# MKV46F16 register map
Vendor: Freescale Semiconductor, Inc.; Series: Kinetis_V; File version: 1.6
CPU: CM4 r0p1, little endian, no MPU, FPU, VTOR, 4 interrupt priority bits
Registers are 32-bit, read-write, reset 0x0 unless marked. A register's access mark holds for its fields unless they carry their own. Offsets are from the block's base; [hi:lo] are bit positions; {n}, {i} and the like mark numbered series; 'fields as' and 'values as' point back to an identical list.

## XBARA — Crossbar Switch
Base 0x40059000; register names take the prefix XBARA_
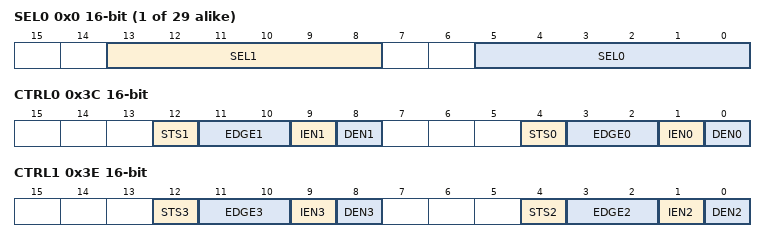
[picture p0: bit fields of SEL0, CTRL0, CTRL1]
{0x0+2i} SEL{i} 16-bit (i=0..28) — Crossbar A Select Register {i}
  [13:8] SEL{2i+1} — Input (XBARA_INn) to be muxed to XBARA_OUT{2i+1} (refer to Functional Description section for input/output assignment)
  [5:0] SEL{2i} — Input (XBARA_INn) to be muxed to XBARA_OUT{2i} (refer to Functional Description section for input/output assignment)
0x3A SEL29 16-bit — Crossbar A Select Register 29
  [5:0] SEL58 — Input (XBARA_INn) to be muxed to XBARA_OUT58 (refer to Functional Description section for input/output assignment)
0x3C CTRL0 16-bit — Crossbar A Control Register 0
  [12] STS1 — Edge detection status for XBAR_OUT1
    0=Active edge not yet detected on XBAR_OUT1; 1=Active edge detected on XBAR_OUT1
  [11:10] EDGE1 — Active edge for edge detection on XBAR_OUT1
    0=STS1 never asserts; 1=STS1 asserts on rising edges of XBAR_OUT1; 2=STS1 asserts on falling edges of XBAR_OUT1; 3=STS1 asserts on rising and falling edges of XBAR_OUT1
  [9] IEN1 — Interrupt Enable for XBAR_OUT1
    0=Interrupt disabled; 1=Interrupt enabled
  [8] DEN1 — DMA Enable for XBAR_OUT1
    0=DMA disabled; 1=DMA enabled
  [4] STS0 — Edge detection status for XBAR_OUT0
    0=Active edge not yet detected on XBAR_OUT0; 1=Active edge detected on XBAR_OUT0
  [3:2] EDGE0 — Active edge for edge detection on XBAR_OUT0
    0=STS0 never asserts; 1=STS0 asserts on rising edges of XBAR_OUT0; 2=STS0 asserts on falling edges of XBAR_OUT0; 3=STS0 asserts on rising and falling edges of XBAR_OUT0
  [1] IEN0 — Interrupt Enable for XBAR_OUT0
    0=Interrupt disabled; 1=Interrupt enabled
  [0] DEN0 — DMA Enable for XBAR_OUT0
    0=DMA disabled; 1=DMA enabled
0x3E CTRL1 16-bit — Crossbar A Control Register 1
  [12] STS3 — Edge detection status for XBAR_OUT3
    0=Active edge not yet detected on XBAR_OUT3; 1=Active edge detected on XBAR_OUT3
  [11:10] EDGE3 — Active edge for edge detection on XBAR_OUT3
    0=STS3 never asserts; 1=STS3 asserts on rising edges of XBAR_OUT3; 2=STS3 asserts on falling edges of XBAR_OUT3; 3=STS3 asserts on rising and falling edges of XBAR_OUT3
  [9] IEN3 — Interrupt Enable for XBAR_OUT3
    0=Interrupt disabled; 1=Interrupt enabled
  [8] DEN3 — DMA Enable for XBAR_OUT3
    0=DMA disabled; 1=DMA enabled
  [4] STS2 — Edge detection status for XBAR_OUT2
    0=Active edge not yet detected on XBAR_OUT2; 1=Active edge detected on XBAR_OUT2
  [3:2] EDGE2 — Active edge for edge detection on XBAR_OUT2
    0=STS2 never asserts; 1=STS2 asserts on rising edges of XBAR_OUT2; 2=STS2 asserts on falling edges of XBAR_OUT2; 3=STS2 asserts on rising and falling edges of XBAR_OUT2
  [1] IEN2 — Interrupt Enable for XBAR_OUT2
    0=Interrupt disabled; 1=Interrupt enabled
  [0] DEN2 — DMA Enable for XBAR_OUT2
    0=DMA disabled; 1=DMA enabled

## XBARB — Crossbar Switch
Base 0x4005A000; register names take the prefix XBARB_
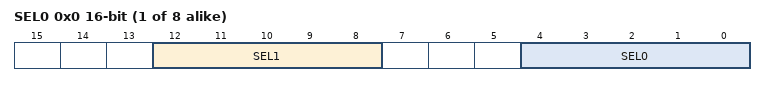
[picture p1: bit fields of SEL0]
{0x0+2i} SEL{i} 16-bit (i=0..7) — Crossbar B Select Register {i}
  [12:8] SEL{2i+1} — Input (XBARB_INn) to be muxed to XBARB_OUT{2i+1} (refer to Functional Description section for input/output assignment)
  [4:0] SEL{2i} — Input (XBARB_INn) to be muxed to XBARB_OUT{2i} (refer to Functional Description section for input/output assignment)

## AOI — AND/OR/INVERT module
Base 0x4005B000; register names take the prefix AOI_
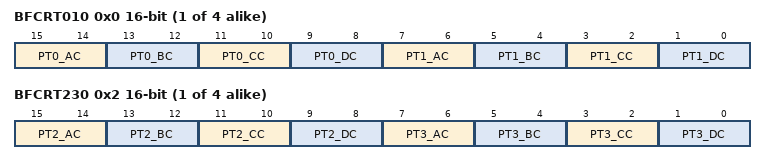
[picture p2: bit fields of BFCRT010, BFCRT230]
{0x0+4i} BFCRT01{i} (i=0..3) 16-bit — Boolean Function Term 0 and 1 Configuration Register for EVENTn
  [15:14] PT0_AC — Product term 0, A input configuration
    0=Force the A input in this product term to a logical zero; 1=Pass the A input in this product term; 2=Complement the A input in this product term; 3=Force the A input in this product term to a logical one
  [13:12] PT0_BC — Product term 0, B input configuration
    0=Force the B input in this product term to a logical zero; 1=Pass the B input in this product term; 2=Complement the B input in this product term; 3=Force the B input in this product term to a logical one
  [11:10] PT0_CC — Product term 0, C input configuration
    0=Force the C input in this product term to a logical zero; 1=Pass the C input in this product term; 2=Complement the C input in this product term; 3=Force the C input in this product term to a logical one
  [9:8] PT0_DC — Product term 0, D input configuration
    0=Force the D input in this product term to a logical zero; 1=Pass the D input in this product term; 2=Complement the D input in this product term; 3=Force the D input in this product term to a logical one
  [7:6] PT1_AC — Product term 1, A input configuration
    values as PT0_AC
  [5:4] PT1_BC — Product term 1, B input configuration
    values as PT0_BC
  [3:2] PT1_CC — Product term 1, C input configuration
    values as PT0_CC
  [1:0] PT1_DC — Product term 1, D input configuration
    values as PT0_DC
{0x2+4i} BFCRT23{i} (i=0..3) 16-bit — Boolean Function Term 2 and 3 Configuration Register for EVENTn
  [15:14] PT2_AC — Product term 2, A input configuration
    values as BFCRT010.PT0_AC
  [13:12] PT2_BC — Product term 2, B input configuration
    values as BFCRT010.PT0_BC
  [11:10] PT2_CC — Product term 2, C input configuration
    values as BFCRT010.PT0_CC
  [9:8] PT2_DC — Product term 2, D input configuration
    values as BFCRT010.PT0_DC
  [7:6] PT3_AC — Product term 3, A input configuration
    values as BFCRT010.PT0_AC
  [5:4] PT3_BC — Product term 3, B input configuration
    values as BFCRT010.PT0_BC
  [3:2] PT3_CC — Product term 3, C input configuration
    values as BFCRT010.PT0_CC
  [1:0] PT3_DC — Product term 3, D input configuration
    values as BFCRT010.PT0_DC
